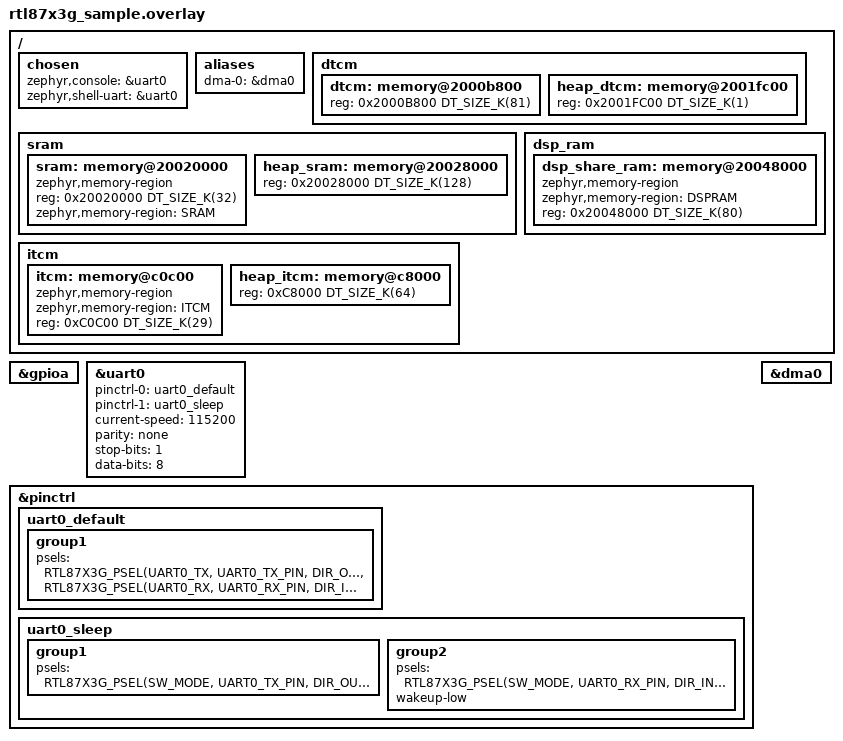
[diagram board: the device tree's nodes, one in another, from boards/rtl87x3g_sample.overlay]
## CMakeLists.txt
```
#
# Copyright (c) 2026, Realtek Semiconductor Corporation
#
# SPDX-License-Identifier: LicenseRef-Realtek-5-Clause
#

message(STATUS "CMAKELIST FOLDER: ${CMAKE_CURRENT_SOURCE_DIR}")

cmake_minimum_required(VERSION 3.20.0)

#===========version generation===========
include(${CMAKE_CURRENT_SOURCE_DIR}/../../cmake/version_generate.cmake)
generate_version()
#===========version generation===========
#===========post build===========
# post build should be called before find_package
include(${CMAKE_CURRENT_SOURCE_DIR}/../../cmake/post_build.cmake)
rtk_post_build()
#===========post build===========

find_package(Zephyr REQUIRED HINTS $ENV{ZEPHYR_BASE})
project(ble_central)

FILE(GLOB app_sources src/*.c)
target_sources(app PRIVATE
  ${app_sources}
  )

set(sources
   ${ZEPHYR_REALTEK_APP_MODULE_DIR}/subsys/bluetooth/gatt_client/bt_ext_ftl.c
   ${ZEPHYR_REALTEK_APP_MODULE_DIR}/subsys/bluetooth/gatt_client/gattc_tbl_storage.c
   )

set(headers
    #header files from app
	src/
    #header files from libs
    ${ZEPHYR_REALTEK_APP_MODULE_DIR}/subsys/bluetooth/gatt_client
    )

foreach(header ${headers})
    if(EXISTS ${header})
        zephyr_include_directories(${header})
    else()
        message(FATAL_ERROR "header file directory does not exist: ${header}. Current cmakelist: ${CMAKE_CURRENT_SOURCE_DIR}")
    endif()
endforeach()

foreach(src ${sources})
    if(EXISTS ${src})
        target_sources(app PRIVATE ${src})
    else()
        message(FATAL_ERROR "source file does not exist: ${src}. Current cmakelist: ${CMAKE_CURRENT_SOURCE_DIR}")
    endif()
endforeach()

target_precompile_headers(app PUBLIC
	          ${CMAKE_CURRENT_SOURCE_DIR}/src/app_lea_cap_ini_flags.h
			  )

target_include_directories(app PRIVATE src)
```

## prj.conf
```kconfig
# nothing here
CONFIG_REALTEK_SUBSYS_BLE_MGR=y
CONFIG_REALTEK_SUBSYS_SYSM=y
CONFIG_REALTEK_SUBSYS_BLE_AUDIO=y

# Network shell
CONFIG_SERIAL=y
CONFIG_UART_CONSOLE=y
CONFIG_UART_INTERRUPT_DRIVEN=y
CONFIG_UART_ASYNC_API=y
CONFIG_SHELL=y
CONFIG_SHELL_BACKEND_SERIAL=y
CONFIG_LOG_RTK=n
CONFIG_PRINTK=y
CONFIG_HEAP_MEM_POOL_SIZE=1024
CONFIG_CONSOLE=y
#CONFIG_STDOUT_CONSOLE=y

#CONFIG_UART_SHELL_ON_DEV_NAME="UART_2"
#CONFIG_SHELL_PROMPT_UART="uart:~$ "
```

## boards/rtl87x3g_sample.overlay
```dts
/*
 * Copyright(c) 2024, Realtek Semiconductor Corporation.
 *
 * SPDX-License-Identifier: Apache-2.0
 */

#include <zephyr/dt-bindings/gpio/realtek-rtl87x3g-gpio.h>
#include <dt-bindings/pinctrl/rtl87x3g-pinctrl.h>
#include <dt-bindings/input/input-event-codes.h>
#include "../board.h"

&gpioa {
	status = "okay";
};

/ {
    chosen {
        zephyr,console = &uart0;
        zephyr,shell-uart = &uart0;
    };
};

/**
#define GDMA_Handshake_UART0_TX                                     (0)
#define GDMA_Handshake_UART0_RX                                     (1)
#define GDMA_Handshake_UART2_TX                                     (2)
#define GDMA_Handshake_UART2_RX                                     (3)
#define GDMA_Handshake_UART3_TX                                     (48)
#define GDMA_Handshake_UART3_RX                                     (49)
#define GDMA_Handshake_UART4_TX                                     (50)
#define GDMA_Handshake_UART4_RX                                     (51)
#define GDMA_Handshake_UART5_TX                                     (52)
#define GDMA_Handshake_UART5_RX                                     (53)
*/

&uart0 {
	pinctrl-0 = <&uart0_default>;
	pinctrl-1 = <&uart0_sleep>;
	pinctrl-names = "default", "sleep";
	status = "okay";
	current-speed = <115200>;
	parity = "none";
	stop-bits = "1";
	data-bits = <8>;
	//dmas = <&dma0 2 3 0xa>, <&dma0 3 2 0x10021>;
	//dma-names = "rx", "tx";
};

&pinctrl
{
	uart0_default:uart0_default {
		group1 {
			psels = <RTL87X3G_PSEL(UART0_TX, UART0_TX_PIN, DIR_OUT, DRV_HIGH, PULL_UP)>,
			<RTL87X3G_PSEL(UART0_RX, UART0_RX_PIN, DIR_IN, DRV_HIGH, PULL_UP)>;
		};
	};

	uart0_sleep:uart0_sleep {
		group1 {
			psels = <RTL87X3G_PSEL(SW_MODE, UART0_TX_PIN, DIR_OUT, DRV_HIGH, PULL_UP)>;
		};
		group2 {
			psels = <RTL87X3G_PSEL(SW_MODE, UART0_RX_PIN, DIR_IN, DRV_HIGH, PULL_UP)>;
			wakeup-low;
		};
	};
};

&dma0 {
	status = "okay";
};

&gpioa {
	status = "okay";
};

/*delete-node only support nodes with lable */
/delete-node/ &dtcm;
/delete-node/ &heap_dtcm;
/delete-node/ &sram;
/delete-node/ &heap_sram;
/delete-node/ &itcm;
/delete-node/ &heap_itcm;
/delete-node/ &dsp_share_ram;

/ {
	aliases {
		dma-0 = &dma0;
    };

	/* DTCM addr: 0x20000000~0x20020000, total size: 128KByte.
	 * The front 46Kbyte was taken by RTK internal.
	 * If users wants to increase global variables and zephyr static heap,
	 * please follow the steps:
	 * 1. increase dtcm size value "reg = <0x2000B800 DT_SIZE_K(NEW_SIZE)>"
	 * 2. modify heap_dtcm addr label "heap_dtcm: memory@NEW_ADDR"
	 * 3. modify heap_dtcm reg addr "reg = <NEW_ADDR DT_SIZE_K(NEW_SIZE)>"
	 * 4. decrease heap_dtcm size value "reg = <NEW_ADDR DT_SIZE_K(NEW_SIZE)>"
	 * Warning:
	 * 1. the dtcm address should NOT modified!
	 * 2. the dtcm plus heap_dtcm size should NOT exceed 82KByte!
	 */
	dtcm {
		dtcm: memory@2000b800 {
			device_type = "dtcm region";
			reg = <0x2000B800 DT_SIZE_K(81)>;
		};
		heap_dtcm: memory@2001fc00 {
			device_type = "heap dtcm region";
			reg = <0x2001FC00 DT_SIZE_K(1)>;
		};
	};
	/* sram addr: 0x20020000~0x20048000, total size: 160KByte.
	 * call zephyr_code_relocate(FILES xxx.x LOCATION SRAM) at cmakelist could relocate variables on sram.
	 * for more information, please refer to https://docs.zephyrproject.org/latest/kernel/code-relocation.html
	 * If users wants to increase sram size, please follow the steps:
	 * 1. increase sram size value "reg = <0x20020000 DT_SIZE_K(NEW_SIZE)>"
	 * 2. modify heap_sram addr label "heap_sram: memory@NEW_ADDR"
	 * 3. modify heap_sram reg addr "reg = <NEW_ADDR DT_SIZE_K(NEW_SIZE)>"
	 * 4. decrease heap_sram size value "reg = <NEW_ADDR DT_SIZE_K(NEW_SIZE)>"
	 * Warning:
	 * 1. the sram address should NOT modified!
	 * 2. the sram plus heap_sram size should NOT exceed 160KByte!
	 */
	sram {
		sram: memory@20020000 {
			device_type = "sram region";
			compatible = "zephyr,memory-region", "mmio-sram";
			reg = <0x20020000 DT_SIZE_K(32)>;
			zephyr,memory-region = "SRAM";
		};
		heap_sram: memory@20028000 {
			device_type = "heap sram region";
			reg = <0x20028000 DT_SIZE_K(128)>;
		};
	};

	itcm {
		itcm: memory@c0c00 {
			device_type = "itcm region";
			compatible = "zephyr,memory-region", "arm,itcm";
			zephyr,memory-region = "ITCM";
			reg = <0xC0C00 DT_SIZE_K(29)>;
		};
		heap_itcm: memory@c8000 {
			device_type = "heap itcm region";
			reg = <0xC8000 DT_SIZE_K(64)>;
		};
	};

	dsp_ram {
		dsp_share_ram: memory@20048000 {
			compatible = "zephyr,memory-region";
			device_type = "dsp_share_ram region";
			zephyr,memory-region = "DSPRAM";
			reg = <0x20048000 DT_SIZE_K(80)>;
		};
	};
};
```

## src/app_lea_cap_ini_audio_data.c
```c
/*
 * Copyright (c) 2026, Realtek Semiconductor Corporation
 *
 * SPDX-License-Identifier: LicenseRef-Realtek-5-Clause
 */

#include "os_queue.h"
#include "stdlib.h"
#include "trace.h"
#include "gap.h"
#include "gap_iso_data.h"
#include "bt_direct_msg.h"
#include "app_lea_cap_ini_main.h"
#include "app_lea_cap_ini_audio_data.h"
#include "ble_audio_def.h"
#include "codec_qos.h"
#if APP_LEA_INPUT_AUDIO_DATA_TEST
#include "app_timer.h"
#endif

#if APP_LEA_INPUT_AUDIO_DATA_TEST
typedef enum
{
    APP_LEA_SEND_ISO_DATA = 0x00,
} T_APP_LEA_TIMER;

static uint8_t app_lea_timer_idx_send_iso_data = 0;
static uint8_t app_lea_timer_id = 0;

const uint8_t lc3_16_2_encoded_data[40] = {0x46, 0xC2, 0x6C, 0x27, 0x41, 0x23, 0x1E, 0x02, 0xE6, 0x7A, 0x04,
                                           0xAB, 0x54, 0x34, 0xFB, 0x6A, 0x0A, 0x24, 0x02, 0x8A, 0xFA, 0x00,
                                           0x00, 0x39, 0x4F, 0x96, 0x0D, 0x38, 0xA7, 0x57, 0xE2, 0x24, 0x56,
                                           0x5F, 0xF1, 0xCB, 0x97, 0x20, 0xF8, 0x9B
                                          };
const uint8_t lc3_16_2_2c_encoded_data[80] = {0x46, 0xC2, 0x6C, 0x27, 0x41, 0x23, 0x1E, 0x02, 0xE6, 0x7A, 0x04,
                                              0xAB, 0x54, 0x34, 0xFB, 0x6A, 0x0A, 0x24, 0x02, 0x8A, 0xFA, 0x00,
                                              0x00, 0x39, 0x4F, 0x96, 0x0D, 0x38, 0xA7, 0x57, 0xE2, 0x24, 0x56,
                                              0x5F, 0xF1, 0xCB, 0x97, 0x20, 0xF8, 0x9B,
                                              0x46, 0xC2, 0x6C, 0x27, 0x41, 0x23, 0x1E, 0x02, 0xE6, 0x7A, 0x04,
                                              0xAB, 0x54, 0x34, 0xFB, 0x6A, 0x0A, 0x24, 0x02, 0x8A, 0xFA, 0x00,
                                              0x00, 0x39, 0x4F, 0x96, 0x0D, 0x38, 0xA7, 0x57, 0xE2, 0x24, 0x56,
                                              0x5F, 0xF1, 0xCB, 0x97, 0x20, 0xF8, 0x9B
                                             };
const uint8_t lc3_16_1_encoded_data[30] = {0x1D,  0x92,  0xB3,  0x67,  0xDE,  0xF5,  0xD0,  0x46,  0xEB,  0xC7,  0xDD,  0x69,  0x89,  0xD8,
                                           0xEA,  0xD5,  0x42,  0x22,  0x4C,  0xBB,  0x53,  0xF9,  0x0D,  0xED,  0xD8,  0xE5,  0x3C,  0xA0,
                                           0xCA,  0x57
                                          };
void app_lea_test_iso_data_send(void)
{
    T_GAP_CAUSE cause = GAP_CAUSE_SUCCESS;
    T_APP_LEA_ISO_CHANN *p_iso_chann = NULL;

    for (uint8_t i = 0; i < app_db.iso_input_queue.count; i++)
    {
        p_iso_chann = (T_APP_LEA_ISO_CHANN *)os_queue_peek(&app_db.iso_input_queue, i);
        if (p_iso_chann->iso_sdu_len != 0)
        {
            cause = gap_iso_send_data((uint8_t *)p_iso_chann->p_encoded_data,
                                      p_iso_chann->iso_conn_handle,
                                      p_iso_chann->iso_sdu_len,
                                      false,
                                      (p_iso_chann->pkt_seq_num * p_iso_chann->sdu_interval),
                                      p_iso_chann->pkt_seq_num);
            if (cause != GAP_CAUSE_SUCCESS)
            {
                goto error;
            }
        }
        p_iso_chann->pkt_seq_num++;
    }
    return;
error:
    APP_PRINT_ERROR1("app_lea_test_iso_data_send: failed, cause 0x%x", cause);
    return;
}

static void app_lea_timer_timeout_cb(uint8_t timer_evt, uint16_t param)
{
    switch (timer_evt)
    {
    case APP_LEA_SEND_ISO_DATA:
        {
            app_lea_test_iso_data_send();
        }
        break;

    default:
        break;
    }
}

static void app_lea_test_start_iso_data_timer(uint32_t timeout_ms)
{
    if (app_lea_timer_id == 0)
    {
        app_timer_reg_cb(app_lea_timer_timeout_cb, &app_lea_timer_id);
    }
    app_start_timer(&app_lea_timer_idx_send_iso_data, "iso_data",
                    app_lea_timer_id, APP_LEA_SEND_ISO_DATA, 0, true,
                    timeout_ms);
}


void app_lea_test_iso_chann_remove(void)
{
    APP_PRINT_INFO1("app_lea_test_iso_chann_remove: iso_input_queue %d",
                    app_db.iso_input_queue.count);
    if (app_db.iso_input_queue.count == 0)
    {
        app_stop_timer(&app_lea_timer_idx_send_iso_data);
    }
}

void app_lea_test_iso_chann_add(T_APP_LEA_ISO_CHANN *p_iso_chann)
{
    uint8_t err_idx = 0;

    codec_max_sdu_len_get(&p_iso_chann->codec_data, &p_iso_chann->iso_sdu_len);
    codec_sdu_interval_get(&p_iso_chann->codec_data, &p_iso_chann->sdu_interval);
    p_iso_chann->pkt_seq_num = 1;

    if (p_iso_chann->codec_data.sample_frequency == SAMPLING_FREQUENCY_CFG_16K)
    {
        if (p_iso_chann->codec_data.frame_duration == FRAME_DURATION_CFG_10_MS)
        {
            if (p_iso_chann->iso_sdu_len == sizeof(lc3_16_2_encoded_data))
            {
                p_iso_chann->p_encoded_data = lc3_16_2_encoded_data;
            }
            else if (p_iso_chann->iso_sdu_len == sizeof(lc3_16_2_2c_encoded_data))
            {
                p_iso_chann->p_encoded_data = lc3_16_2_2c_encoded_data;
            }
            else
            {
                err_idx = 3;
                goto failed;
            }
        }
        else if (p_iso_chann->codec_data.frame_duration == FRAME_DURATION_CFG_7_5_MS)
        {
            if (p_iso_chann->iso_sdu_len == sizeof(lc3_16_1_encoded_data))
            {
                p_iso_chann->p_encoded_data = lc3_16_1_encoded_data;
            }
            else
            {
                err_idx = 4;
                goto failed;
            }
        }
    }
    else
    {
        err_idx = 10;
        goto failed;
    }
    APP_PRINT_INFO2("app_lea_test_iso_chann_add: sdu %d, interval %d", p_iso_chann->iso_sdu_len,
                    p_iso_chann->sdu_interval / 1000);

    app_lea_test_start_iso_data_timer(p_iso_chann->sdu_interval / 1000);

    return;
failed:
    APP_PRINT_ERROR1("app_lea_test_iso_chann_add: failed err_idx %d", err_idx);
    return;
}
#endif

static T_APP_LEA_ISO_CHANN *app_lea_find_iso_chann(uint16_t iso_conn_handle, uint8_t direction)
{
    int i;
    T_APP_LEA_ISO_CHANN *p_iso_chann = NULL;
    if (direction == DATA_PATH_INPUT_FLAG)
    {
        for (i = 0; i < app_db.iso_input_queue.count; i++)
        {
            p_iso_chann = (T_APP_LEA_ISO_CHANN *)os_queue_peek(&app_db.iso_input_queue, i);
            if (p_iso_chann->iso_conn_handle == iso_conn_handle)
            {
                return p_iso_chann;
            }
        }
    }
    else
    {
        for (i = 0; i < app_db.iso_output_queue.count; i++)
        {
            p_iso_chann = (T_APP_LEA_ISO_CHANN *)os_queue_peek(&app_db.iso_output_queue, i);
            if (p_iso_chann->iso_conn_handle == iso_conn_handle)
            {
                return p_iso_chann;
            }
        }
    }
    return NULL;
}

T_APP_LEA_ISO_CHANN *app_lea_add_iso_chann(uint16_t iso_conn_handle, uint8_t direction)
{
    T_APP_LEA_ISO_CHANN *p_iso_chann;

    p_iso_chann = app_lea_find_iso_chann(iso_conn_handle, direction);
    if (p_iso_chann)
    {
        return p_iso_chann;
    }
    p_iso_chann = calloc(1, sizeof(T_APP_LEA_ISO_CHANN));
    if (p_iso_chann)
    {
        p_iso_chann->iso_conn_handle = iso_conn_handle;
        p_iso_chann->path_direction = direction;
        if (direction == DATA_PATH_INPUT_FLAG)
        {
            os_queue_in(&app_db.iso_input_queue, p_iso_chann);
        }
        else
        {
            os_queue_in(&app_db.iso_output_queue, p_iso_chann);
        }
        APP_PRINT_INFO2("app_lea_add_iso_chann: iso_conn_handle 0x%x, direction %d",
                        iso_conn_handle, direction);
    }
    return p_iso_chann;
}

static void app_lea_remove_iso_chann(uint16_t iso_conn_handle, uint8_t direction)
{
    int i;
    T_APP_LEA_ISO_CHANN *p_iso_chann = NULL;
    APP_PRINT_INFO2("app_lea_remove_iso_chann: iso_conn_handle 0x%x, direction %d",
                    iso_conn_handle, direction);
    if (direction == DATA_PATH_INPUT_FLAG)
    {
        for (i = 0; i < app_db.iso_input_queue.count; i++)
        {
            p_iso_chann = (T_APP_LEA_ISO_CHANN *)os_queue_peek(&app_db.iso_input_queue, i);
            if (p_iso_chann->iso_conn_handle == iso_conn_handle)
            {
                os_queue_delete(&app_db.iso_input_queue, p_iso_chann);
                free(p_iso_chann);
#if APP_LEA_INPUT_AUDIO_DATA_TEST
                app_lea_test_iso_chann_remove();
#endif
                return;
            }
        }
    }
    else
    {
        for (i = 0; i < app_db.iso_output_queue.count; i++)
        {
            p_iso_chann = (T_APP_LEA_ISO_CHANN *)os_queue_peek(&app_db.iso_output_queue, i);
            if (p_iso_chann->iso_conn_handle == iso_conn_handle)
            {
                os_queue_delete(&app_db.iso_output_queue, p_iso_chann);
                free(p_iso_chann);
                return;
            }
        }
    }
}


void app_lea_handle_data_path_setup(T_LEA_SETUP_DATA_PATH *p_data)
{
    T_APP_LEA_ISO_CHANN *p_iso_chann = app_lea_find_iso_chann(p_data->iso_conn_handle,
                                                              p_data->path_direction);
    uint8_t chnl_cnt;
    uint8_t blocks_num = 1;

    if (p_iso_chann != NULL)
    {
        APP_PRINT_WARN0("app_lea_handle_data_path_setup: iso channel already exist");
        return;
    }
    else
    {
        p_iso_chann = app_lea_add_iso_chann(p_data->iso_conn_handle,
                                            p_data->path_direction);
        if (p_iso_chann == NULL)
        {
            return;
        }
        p_iso_chann->iso_mode = p_data->iso_mode;
    }
    p_iso_chann->codec_data = p_data->codec_parsed_data;
    p_iso_chann->presentation_delay = p_data->presentation_delay;
    p_iso_chann->pkt_seq_num = 0;
    if (p_iso_chann->codec_data.audio_channel_allocation == AUDIO_LOCATION_MONO)
    {
        chnl_cnt = 1;
    }
    else
    {
        chnl_cnt = __builtin_popcount(p_iso_chann->codec_data.audio_channel_allocation);
    }
    if (p_iso_chann->codec_data.type_exist & CODEC_CFG_TYPE_BLOCKS_PER_SDU_EXIST)
    {
        blocks_num = p_iso_chann->codec_data.codec_frame_blocks_per_sdu;
    }
    p_iso_chann->frame_num = blocks_num * chnl_cnt;

    APP_PRINT_INFO6("app_lea_handle_data_path_setup: cis handle 0x%04x, frame_num %d, "
                    "dir %u, sample_frequency 0x%x, audio_channel_allocation 0x%08x, presentation_delay 0x%x",
                    p_iso_chann->iso_conn_handle, p_iso_chann->frame_num,
                    p_iso_chann->path_direction,
                    p_iso_chann->codec_data.sample_frequency,
                    p_iso_chann->codec_data.audio_channel_allocation,
                    p_iso_chann->presentation_delay);
#if APP_LEA_INPUT_AUDIO_DATA_TEST
    if (p_data->path_direction == DATA_PATH_INPUT_FLAG)
    {
        app_lea_test_iso_chann_add(p_iso_chann);
    }
#endif
}

void app_lea_handle_data_path_remove(T_LEA_REMOVE_DATA_PATH *p_data)
{
    T_APP_LEA_ISO_CHANN *p_iso_chann = app_lea_find_iso_chann(p_data->iso_conn_handle,
                                                              p_data->path_direction);
    if (p_iso_chann != NULL)
    {
        app_lea_remove_iso_chann(p_data->iso_conn_handle, p_data->path_direction);
    }
}

void app_lea_data_direct_cb(uint8_t cb_type, void *p_cb_data)
{
    T_BT_DIRECT_CB_DATA *p_data = (T_BT_DIRECT_CB_DATA *)p_cb_data;

    switch (cb_type)
    {
    case BT_DIRECT_MSG_ISO_DATA_IND:
        {
#if 0
            APP_PRINT_TRACE5("app_lea_data_direct_cb: conn_handle 0x%x, iso_sdu_len %d, pkt_seq_num 0x%x, time_stamp 0x%x, pkt_status_flag 0x%x",
                             p_data->p_bt_direct_iso->conn_handle, p_data->p_bt_direct_iso->iso_sdu_len,
                             p_data->p_bt_direct_iso->pkt_seq_num, p_data->p_bt_direct_iso->time_stamp,
                             p_data->p_bt_direct_iso->pkt_status_flag);
#endif
#if 0
            uint8_t *p_iso_data = p_data->p_bt_direct_iso->p_buf + p_data->p_bt_direct_iso->offset;
            APP_PRINT_INFO5("app_lea_data_direct_cb: BT_DIRECT_MSG_ISO_DATA_IND, iso_sdu_len 0x%x, p_buf %p, offset %d, p_data %p, data %b",
                            p_data->p_bt_direct_iso->iso_sdu_len, p_data->p_bt_direct_iso->p_buf,
                            p_data->p_bt_direct_iso->offset, p_iso_data, TRACE_BINARY(p_data->p_bt_direct_iso->iso_sdu_len,
                                                                                      p_iso_data));
#endif
            APP_PRINT_TRACE5("app_lea_data_direct_cb: conn_handle 0x%x, iso_sdu_len %d, pkt_seq_num 0x%x, time_stamp 0x%x, pkt_status_flag 0x%x",
                             p_data->p_bt_direct_iso->conn_handle, p_data->p_bt_direct_iso->iso_sdu_len,
                             p_data->p_bt_direct_iso->pkt_seq_num, p_data->p_bt_direct_iso->time_stamp,
                             p_data->p_bt_direct_iso->pkt_status_flag);

            if (p_data->p_bt_direct_iso->pkt_status_flag != ISOCH_DATA_PKT_STATUS_VALID_DATA)
            {
                gap_iso_data_cfm(p_data->p_bt_direct_iso->p_buf);
                break;
            }

            T_APP_LEA_ISO_CHANN *p_iso_chann = app_lea_find_iso_chann(p_data->p_bt_direct_iso->conn_handle,
                                                                      DATA_PATH_OUTPUT_FLAG);
            if (p_iso_chann != NULL)
            {
#if 0
                //Just for sample. Application can send the data to DSP.
                uint16_t written_len;
                T_AUDIO_STREAM_STATUS status;

                if (p_data->p_bt_direct_iso->iso_sdu_len != 0)
                {
                    status = AUDIO_STREAM_STATUS_CORRECT;
                }
                else
                {
                    status = AUDIO_STREAM_STATUS_LOST;
                }
                audio_track_write(handle, p_data->p_bt_direct_iso->time_stamp,
                                  p_data->p_bt_direct_iso->pkt_seq_num,
                                  status,
                                  p_iso_chann->frame_num,
                                  p_data->p_bt_direct_iso->p_buf + p_data->p_bt_direct_iso->offset,
                                  p_data->p_bt_direct_iso->iso_sdu_len,
                                  &written_len);
#endif
            }

            gap_iso_data_cfm(p_data->p_bt_direct_iso->p_buf);
        }
        break;

    default:
        APP_PRINT_ERROR1("app_lea_data_direct_cb: unhandled cb_type 0x%x", cb_type);
        break;
    }
}

void app_lea_audio_data_init(void)
{
    os_queue_init(&app_db.iso_input_queue);
    os_queue_init(&app_db.iso_output_queue);
    gap_register_direct_cb(app_lea_data_direct_cb);
}
```

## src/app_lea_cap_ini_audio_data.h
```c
/*
 * Copyright (c) 2026, Realtek Semiconductor Corporation
 *
 * SPDX-License-Identifier: LicenseRef-Realtek-5-Clause
 */

#ifndef _APP_LEA_CAP_INI_AUDIO_DATA_H_
#define _APP_LEA_CAP_INI_AUDIO_DATA_H_

#ifdef  __cplusplus
extern "C" {
#endif      /* __cplusplus */

#include "codec_def.h"
#include "ble_isoch_def.h"

#define CIG_ISO_MODE        0x01
#define BIG_ISO_MODE        0x02

typedef struct t_lea_iso_chann
{
    struct t_lea_iso_chann     *p_next;
    uint8_t                     iso_mode;
    uint8_t                     frame_num;
    uint8_t                     path_direction;   //DATA_PATH_INPUT_FLAG or DATA_PATH_OUTPUT_FLAG
    uint16_t                    iso_conn_handle;
    uint16_t                    pkt_seq_num;
    uint32_t                    presentation_delay;
    T_CODEC_CFG                 codec_data;
#if APP_LEA_INPUT_AUDIO_DATA_TEST
    uint16_t                    iso_sdu_len;
    uint32_t                    sdu_interval;
    const uint8_t              *p_encoded_data;
#endif
} T_APP_LEA_ISO_CHANN;

typedef struct
{
    uint8_t iso_mode;
    uint8_t path_direction;//DATA_PATH_INPUT_FLAG or DATA_PATH_OUTPUT_FLAG
    uint16_t iso_conn_handle;
    uint32_t presentation_delay;
    T_CODEC_CFG codec_parsed_data;
} T_LEA_SETUP_DATA_PATH;

typedef struct
{
    uint8_t iso_mode;
    uint8_t path_direction;//DATA_PATH_INPUT_FLAG or DATA_PATH_OUTPUT_FLAG
    uint16_t iso_conn_handle;
} T_LEA_REMOVE_DATA_PATH;

void app_lea_handle_data_path_setup(T_LEA_SETUP_DATA_PATH *p_data);
void app_lea_handle_data_path_remove(T_LEA_REMOVE_DATA_PATH *p_data);
void app_lea_audio_data_init(void);

#ifdef  __cplusplus
}
#endif      /*  __cplusplus */

#endif
```

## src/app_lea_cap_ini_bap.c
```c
/*
 * Copyright (c) 2026, Realtek Semiconductor Corporation
 *
 * SPDX-License-Identifier: LicenseRef-Realtek-5-Clause
 */

#include "stdlib.h"
#include "ble_audio.h"
#include "bap.h"
#include "trace.h"
#include "app_lea_cap_ini_main.h"
#include "app_lea_cap_ini_bap.h"
#include "ble_audio.h"
#include "ble_audio_def.h"
#include "bass_client.h"
#include "metadata_def.h"
#include "base_data_parse.h"
#include "base_data_generate.h"

#if (BAP_BROADCAST_ASSISTANT && BAP_BROADCAST_SOURCE)
void app_lea_link_init_brs_char(T_APP_LE_LINK *p_link, uint8_t brs_char_num)
{
    if (p_link->brs_char_tbl)
    {
        free(p_link->brs_char_tbl);
        p_link->brs_char_num = 0;
        p_link->brs_char_tbl = NULL;
    }
    if (brs_char_num)
    {
        p_link->brs_char_tbl = calloc(1, brs_char_num * sizeof(T_BASS_BRS_CHAR_DB));
        if (p_link->brs_char_tbl)
        {
            T_BASS_BRS_DATA *p_brs_data;

            p_link->brs_char_num = brs_char_num;
            for (uint8_t i = 0; i < brs_char_num; i++)
            {
                p_link->brs_char_tbl[i].instance_id = i;
                p_brs_data = bass_get_brs_data(p_link->conn_handle, i);
                if (p_brs_data)
                {
                    if (p_brs_data->brs_is_used)
                    {
                        p_link->brs_char_tbl[i].brs_is_used = true;
                        p_link->brs_char_tbl[i].source_id = p_brs_data->source_id;
                        p_link->brs_char_tbl[i].handle = app_lea_bsrc_get_handle(p_brs_data->source_address,
                                                                                 p_brs_data->source_address_type,
                                                                                 p_brs_data->source_adv_sid, p_brs_data->broadcast_id);
                    }
                }
            }
        }
    }
}

T_BASS_BRS_CHAR_DB *app_lea_link_find_brs_char(T_APP_LE_LINK *p_link, uint8_t instance_id)
{
    if (instance_id < p_link->brs_char_num)
    {
        return &p_link->brs_char_tbl[instance_id];
    }
    return NULL;
}

T_BASS_BRS_CHAR_DB *app_lea_link_find_brs_char_by_source_handle(T_APP_LE_LINK *p_link,
                                                                T_BROADCAST_SOURCE_HANDLE source_handle)
{
    for (uint8_t i = 0; i < p_link->brs_char_num; i++)
    {
        if (p_link->brs_char_tbl[i].brs_is_used &&
            p_link->brs_char_tbl[i].handle == source_handle)
        {
            return &p_link->brs_char_tbl[i];
        }
    }
    APP_PRINT_TRACE1("app_lea_link_find_brs_char_by_source_handle: not find source_handle %p",
                     source_handle);
    return NULL;
}

void app_lea_link_update_brs_char(T_APP_LE_LINK *p_link, T_BASS_CLIENT_BRS_DATA *p_data)
{
    T_BASS_BRS_CHAR_DB *p_brs_char = app_lea_link_find_brs_char(p_link, p_data->char_instance_id);

    if (p_brs_char)
    {
        if (p_brs_char->brs_is_used != p_data->p_brs_data->brs_is_used)
        {
            if (p_data->p_brs_data->brs_is_used)
            {
                p_brs_char->brs_is_used = true;
                p_brs_char->source_id = p_data->p_brs_data->source_id;
                p_brs_char->handle = app_lea_bsrc_get_handle(p_data->p_brs_data->source_address,
                                                             p_data->p_brs_data->source_address_type,
                                                             p_data->p_brs_data->source_adv_sid, p_data->p_brs_data->broadcast_id);
            }
            else
            {
                p_brs_char->brs_is_used = false;
                p_brs_char->source_id = 0;
                p_brs_char->handle = NULL;
            }
        }
    }
}

void app_lea_link_brs_char_add_source_handle(void)
{
    T_APP_LE_LINK *p_link = NULL;
    uint8_t i;

    for (i = 0; i < APP_MAX_BLE_LINK_NUM; i++)
    {
        if (app_db.le_link[i].used == true &&
            app_db.le_link[i].brs_char_tbl != NULL)
        {
            p_link = &app_db.le_link[i];
            for (uint8_t j = 0; j < p_link->brs_char_num; j++)
            {
                if (p_link->brs_char_tbl[j].brs_is_used &&
                    p_link->brs_char_tbl[j].handle == NULL)
                {
                    T_BASS_BRS_DATA *p_brs_data = bass_get_brs_data(p_link->conn_handle, j);

                    if (p_brs_data)
                    {
                        p_link->brs_char_tbl[j].handle = app_lea_bsrc_get_handle(p_brs_data->source_address,
                                                                                 p_brs_data->source_address_type,
                                                                                 p_brs_data->source_adv_sid, p_brs_data->broadcast_id);
                    }
                }
            }
        }
    }
}

void app_lea_ini_bst_reception_stop(T_BLE_AUDIO_GROUP_HANDLE group_handle,
                                    T_BROADCAST_SOURCE_HANDLE source_handle)
{
    uint8_t dev_num;
    T_AUDIO_DEV_INFO *p_dev_tbl;

    dev_num = ble_audio_group_get_dev_num(group_handle);
    if (dev_num)
    {
        p_dev_tbl = calloc(1, dev_num * sizeof(T_AUDIO_DEV_INFO));
        if (p_dev_tbl)
        {
            if (ble_audio_group_get_info(group_handle, &dev_num, p_dev_tbl))
            {
                for (uint8_t j = 0; j < dev_num; j++)
                {
                    if (p_dev_tbl[j].is_used && p_dev_tbl[j].conn_state == GAP_CONN_STATE_CONNECTED)
                    {
                        T_APP_LE_LINK *p_link = app_link_find_le_link_by_conn_handle(p_dev_tbl[j].conn_handle);
                        if (p_link)
                        {
                            if (p_link->lea_disc_flags & LEA_LINK_DISC_BASS_DONE)
                            {
                                T_BASS_BRS_CHAR_DB *p_brs_char = app_lea_link_find_brs_char_by_source_handle(p_link, source_handle);
                                if (p_brs_char)
                                {
                                    T_BASS_CP_MODIFY_SOURCE modify_src = {0};
                                    T_BASS_CP_BIS_INFO bis_info = {0};

                                    modify_src.source_id = p_brs_char->source_id;
                                    modify_src.pa_sync = BASS_PA_NOT_SYNC;
                                    modify_src.pa_interval = BASS_PA_INTERVAL_UNKNOWN;
                                    modify_src.num_subgroups = 1;
                                    bis_info.bis_sync = 0;
                                    bis_info.metadata_len = 0;
                                    bis_info.p_metadata = NULL;
                                    modify_src.bis_info_size = modify_src.num_subgroups * sizeof(bis_info) + bis_info.metadata_len;
                                    modify_src.p_cp_bis_info = &bis_info;
                                    bass_cp_modify_source(p_link->conn_handle, &modify_src, false);
                                }
                            }
                        }
                    }
                }
            }
            free(p_dev_tbl);
        }
    }
}

void app_lea_ini_bst_reception_remove(T_BLE_AUDIO_GROUP_HANDLE group_handle,
                                      T_BROADCAST_SOURCE_HANDLE source_handle)
{
    uint8_t dev_num;
    T_AUDIO_DEV_INFO *p_dev_tbl;

    dev_num = ble_audio_group_get_dev_num(group_handle);
    if (dev_num)
    {
        p_dev_tbl = calloc(1, dev_num * sizeof(T_AUDIO_DEV_INFO));
        if (p_dev_tbl)
        {
            if (ble_audio_group_get_info(group_handle, &dev_num, p_dev_tbl))
            {
                for (uint8_t j = 0; j < dev_num; j++)
                {
                    if (p_dev_tbl[j].is_used && p_dev_tbl[j].conn_state == GAP_CONN_STATE_CONNECTED)
                    {
                        T_APP_LE_LINK *p_link = app_link_find_le_link_by_conn_handle(p_dev_tbl[j].conn_handle);
                        if (p_link)
                        {
                            APP_PRINT_TRACE2("app_lea_ini_bst_reception_remove: conn_handle 0x%x, lea_disc_flags 0x%x",
                                             p_dev_tbl[j].conn_handle, p_link->lea_disc_flags);
                            if (p_link->lea_disc_flags & LEA_LINK_DISC_BASS_DONE)
                            {
                                T_BASS_BRS_CHAR_DB *p_brs_char = app_lea_link_find_brs_char_by_source_handle(p_link, source_handle);
                                if (p_brs_char)
                                {
                                    T_BASS_CP_REMOVE_SOURCE remove_source;
                                    remove_source.source_id = p_brs_char->source_id;
                                    bass_cp_remove_source(p_link->conn_handle, &remove_source, false);
                                }
                            }
                        }
                    }
                }
            }
            free(p_dev_tbl);
        }
    }
}

void app_lea_ini_bst_start(T_BASS_BRS_CHAR_DB *p_brs_char, uint16_t conn_handle)
{
    uint8_t err_idx = 0;
    uint16_t pa_data_len;
    uint8_t *pa_data = NULL;
    T_BASE_DATA_MAPPING *p_base_mapping = NULL;
    uint32_t bis_array;
    T_BASS_CP_BIS_INFO *p_cp_bis_info = NULL;
    uint16_t meta_data_len = 0;
    uint32_t bis_array_temp = 0;
    uint16_t bis_info_size = 0;
    uint8_t *p_meta_data;

    if (base_data_gen_pa_data(app_db.bsrc_db.group1_idx, &pa_data_len, &pa_data) == false)
    {
        err_idx = 1;
        goto ret;
    }
    p_base_mapping = base_data_parse_data(pa_data_len, pa_data);


    bis_array = bap_pacs_check_cfg_by_base_data(p_base_mapping, conn_handle,
                                                (BA_PACS_CHECK_FILTER_CODEC));
    if (bis_array == 0)
    {
        err_idx = 2;
        goto ret;
    }

    if (p_brs_char)
    {
        T_BASS_BRS_DATA *p_brs_data = bass_get_brs_data(conn_handle, p_brs_char->instance_id);
        if (p_brs_data && p_brs_data->p_cp_bis_info != NULL)
        {
            if (p_brs_data->p_cp_bis_info->bis_sync == bis_array)
            {
                err_idx = 0;
                goto ret;
            }
        }
    }
    for (uint8_t i = 0; i < p_base_mapping->num_subgroups; i++)
    {
        if (p_base_mapping->p_subgroup[i].bis_array & bis_array)
        {
            bis_array_temp |= (p_base_mapping->p_subgroup[i].bis_array & bis_array);
        }
        meta_data_len += p_base_mapping->p_subgroup[i].metadata_len;
    }
    if (bis_array != BASS_CP_BIS_SYNC_NO_PREFER && bis_array != bis_array_temp)
    {
        err_idx = 3;
        goto ret;
    }
    bis_info_size = p_base_mapping->num_subgroups * sizeof(
                        T_BASS_CP_BIS_INFO) + meta_data_len;
    p_cp_bis_info = calloc(1, bis_info_size);
    if (p_cp_bis_info == NULL)
    {
        err_idx = 4;
        goto ret;
    }

    p_meta_data = (uint8_t *)(p_cp_bis_info + p_base_mapping->num_subgroups);
    for (uint8_t i = 0; i < p_base_mapping->num_subgroups; i++)
    {
        if (bis_array == BASS_CP_BIS_SYNC_NO_PREFER)
        {
            p_cp_bis_info[i].bis_sync = BASS_CP_BIS_SYNC_NO_PREFER;
        }
        else
        {
            p_cp_bis_info[i].bis_sync = (p_base_mapping->p_subgroup[i].bis_array & bis_array);
        }
        p_cp_bis_info[i].metadata_len = p_base_mapping->p_subgroup[i].metadata_len;
        if (p_cp_bis_info[i].metadata_len > 0)
        {
            memcpy(p_meta_data, p_base_mapping->p_subgroup[i].p_metadata,
                   p_cp_bis_info[i].metadata_len);
            p_cp_bis_info[i].p_metadata = p_meta_data;
            p_meta_data += p_cp_bis_info->metadata_len;
        }
    }

    if (p_brs_char)
    {
        T_BASS_CP_MODIFY_SOURCE modify_src = {0};

        modify_src.bis_info_size = bis_info_size;
        modify_src.p_cp_bis_info = p_cp_bis_info;
        modify_src.num_subgroups = p_base_mapping->num_subgroups;

        modify_src.source_id = p_brs_char->source_id;
        modify_src.pa_sync = BASS_PA_SYNC_PAST;
        modify_src.pa_interval = BASS_PA_INTERVAL_UNKNOWN;

        if (bass_cp_modify_source(conn_handle, &modify_src, false) == false)
        {
            err_idx = 5;
            goto ret;
        }
    }
    else
    {
        T_BASS_CP_ADD_SOURCE add_src = {0};

        add_src.bis_info_size = bis_info_size;
        add_src.p_cp_bis_info = p_cp_bis_info;
        add_src.num_subgroups = p_base_mapping->num_subgroups;

        add_src.advertiser_address_type = app_db.bsrc_db.cfg_local_addr_type;
        memcpy(add_src.advertiser_address, app_db.bsrc_db.source_address, GAP_BD_ADDR_LEN);
        add_src.advertiser_sid = app_db.bsrc_db.source_adv_sid;
        memcpy(add_src.broadcast_id, app_db.bsrc_db.broadcast_id, BROADCAST_ID_LEN);
        add_src.pa_sync = BASS_PA_SYNC_PAST;
        add_src.pa_interval = BASS_PA_INTERVAL_UNKNOWN;

        if (bass_cp_add_source(conn_handle, &add_src, false) == false)
        {
            err_idx = 6;
            goto ret;
        }
    }

    err_idx = 0;
ret:
    if (pa_data)
    {
        free(pa_data);
    }
    if (p_base_mapping)
    {
        base_data_free(p_base_mapping);
    }
    if (p_cp_bis_info)
    {
        free(p_cp_bis_info);
    }
    if (err_idx != 0)
    {
        APP_PRINT_INFO2("app_lea_ini_bst_start: failed, conn_handle 0x%x, err_idx %d", conn_handle,
                        err_idx);
    }
    return;
}

void app_lea_ini_bst_reception_start(T_BLE_AUDIO_GROUP_HANDLE group_handle,
                                     T_BROADCAST_SOURCE_HANDLE source_handle)
{
    uint8_t dev_num;
    T_AUDIO_DEV_INFO *p_dev_tbl;

    if (app_db.bsrc_db.source_handle == NULL ||
        app_db.bsrc_db.state != BROADCAST_SOURCE_STATE_STREAMING)
    {
        return;
    }

    dev_num = ble_audio_group_get_dev_num(group_handle);
    if (dev_num)
    {
        p_dev_tbl = calloc(1, dev_num * sizeof(T_AUDIO_DEV_INFO));
        if (p_dev_tbl)
        {
            if (ble_audio_group_get_info(group_handle, &dev_num, p_dev_tbl))
            {
                for (uint8_t j = 0; j < dev_num; j++)
                {
                    if (p_dev_tbl[j].is_used && p_dev_tbl[j].conn_state == GAP_CONN_STATE_CONNECTED)
                    {
                        T_APP_LE_LINK *p_link = app_link_find_le_link_by_conn_handle(p_dev_tbl[j].conn_handle);
                        if (p_link)
                        {
                            APP_PRINT_TRACE2("app_lea_ini_bst_reception_start: conn_handle 0x%x, lea_disc_flags 0x%x",
                                             p_dev_tbl[j].conn_handle, p_link->lea_disc_flags);
                            if (p_link->lea_disc_flags & LEA_LINK_DISC_BASS_DONE)
                            {
                                T_BASS_BRS_CHAR_DB *p_brs_char;
                                p_brs_char = app_lea_link_find_brs_char_by_source_handle(p_link, source_handle);
                                app_lea_ini_bst_start(p_brs_char, p_link->conn_handle);
                            }
                        }
                    }
                }
            }
            free(p_dev_tbl);
        }
    }
}
#endif

uint16_t app_lea_ini_bap_handle_msg(T_LE_AUDIO_MSG msg, void *buf)
{
    uint16_t cb_result = BLE_AUDIO_CB_RESULT_SUCCESS;
    T_APP_LE_LINK *p_link = NULL;

    switch (msg)
    {
    case LE_AUDIO_MSG_BAP_DIS_ALL_DONE:
        {
            T_BAP_DIS_ALL_DONE *p_data = (T_BAP_DIS_ALL_DONE *)buf;
            APP_PRINT_INFO5("LE_AUDIO_MSG_BAP_DIS_ALL_DONE: conn_handle 0x%x, cause 0x%x, pacs_is_found %d, sink_pac_num %d, source_pac_num %d",
                            p_data->conn_handle,
                            p_data->cause,
                            p_data->pacs_is_found,
                            p_data->sink_pac_num,
                            p_data->source_pac_num);
            APP_PRINT_INFO5("LE_AUDIO_MSG_BAP_DIS_ALL_DONE: ascs_is_found %d, sink_ase_num %d, source_ase_num %d, bass_is_found %d, brs_char_num %d",
                            p_data->ascs_is_found,
                            p_data->sink_ase_num,
                            p_data->source_ase_num,
                            p_data->bass_is_found,
                            p_data->brs_char_num);
            p_link = app_link_find_le_link_by_conn_handle(p_data->conn_handle);
            if (p_link)
            {
                if (p_data->ascs_is_found)
                {
                    p_link->lea_disc_flags |= LEA_LINK_DISC_ASCS_DONE;
                    p_link->lea_srv_found_flags |= LEA_LINK_DISC_ASCS_DONE;
                }
                if (p_data->pacs_is_found)
                {
                    p_link->lea_disc_flags |= LEA_LINK_DISC_PACS_DONE;
                    p_link->lea_srv_found_flags |= LEA_LINK_DISC_PACS_DONE;
                }
#if (BAP_BROADCAST_ASSISTANT && BAP_BROADCAST_SOURCE)
                if (p_data->bass_is_found)
                {
                    p_link->lea_disc_flags |= LEA_LINK_DISC_BASS_DONE;
                    p_link->lea_srv_found_flags |= LEA_LINK_DISC_BASS_DONE;
                    app_lea_link_init_brs_char(p_link, p_data->brs_char_num);
                }
#endif
            }

        }
        break;

#if (BAP_BROADCAST_ASSISTANT && BAP_BROADCAST_SOURCE)
    case LE_AUDIO_MSG_BASS_CLIENT_CP_RESULT:
        {
            T_BASS_CLIENT_CP_RESULT *p_data = (T_BASS_CLIENT_CP_RESULT *)buf;
            APP_PRINT_INFO2("LE_AUDIO_MSG_BASS_CLIENT_CP_RESULT: conn_handle 0x%x, cause 0x%x",
                            p_data->conn_handle,
                            p_data->cause);
        }
        break;

    case LE_AUDIO_MSG_BASS_CLIENT_SYNC_INFO_REQ:
        {
            T_BASS_CLIENT_SYNC_INFO_REQ *p_data = (T_BASS_CLIENT_SYNC_INFO_REQ *)buf;

            APP_PRINT_INFO2("LE_AUDIO_MSG_BASS_CLIENT_SYNC_INFO_REQ: conn_handle 0x%x, char_instance_id %d",
                            p_data->conn_handle,
                            p_data->char_instance_id);
            p_link = app_link_find_le_link_by_conn_handle(p_data->conn_handle);
            if (p_link)
            {
                T_BASS_BRS_CHAR_DB *p_brs_char = app_lea_link_find_brs_char(p_link, p_data->char_instance_id);
                if (p_brs_char != NULL && p_brs_char->handle != NULL)
                {
                    if (ble_audio_check_remote_features(p_data->conn_handle, LE_SUPPORT_FEATURES_MASK_ARRAY_INDEX3,
                                                        LE_SUPPORT_FEATURES_PAST_RECIPIENT_MASK_BIT))
                    {
                        if (le_check_supported_features(LE_SUPPORT_FEATURES_MASK_ARRAY_INDEX3,
                                                        LE_SUPPORT_FEATURES_PAST_SENDER_MASK_BIT))
                        {
                            T_BASS_PAST_SRV_DATA srv_data;

                            srv_data.adv_a_match_ext_adv = 0;
                            srv_data.adv_a_match_src = 0;
                            srv_data.source_id = p_data->p_brs_data->source_id;
                            bass_past_by_local_src(p_brs_char->handle, p_data->conn_handle,
                                                   srv_data);
                        }
                    }
                }
            }
        }
        break;

    case LE_AUDIO_MSG_BASS_CLIENT_BRS_DATA:
        {
            T_BASS_CLIENT_BRS_DATA *p_data = (T_BASS_CLIENT_BRS_DATA *)buf;
            APP_PRINT_INFO4("LE_AUDIO_MSG_BASS_CLIENT_BRS_DATA: conn_handle 0x%x, notify %d, read_cause 0x%x, char_instance_id %d",
                            p_data->conn_handle, p_data->notify, p_data->read_cause, p_data->char_instance_id);
            if (p_data->p_brs_data)
            {
                if (p_data->p_brs_data->brs_is_used)
                {
                    APP_PRINT_INFO7("LE_AUDIO_MSG_BASS_CLIENT_BRS_DATA: source_id %d, source_address_type 0x%x, source_address %s, source_adv_sid %d, pa_sync_state %d, bis_sync_state 0x%x, big_encryption %d",
                                    p_data->p_brs_data->source_id,
                                    p_data->p_brs_data->source_address_type,
                                    TRACE_BDADDR(p_data->p_brs_data->source_address),
                                    p_data->p_brs_data->source_adv_sid,
                                    p_data->p_brs_data->pa_sync_state,
                                    p_data->p_brs_data->bis_sync_state,
                                    p_data->p_brs_data->big_encryption);
                    if (p_data->p_brs_data->num_subgroups)
                    {
                        APP_PRINT_INFO4("LE_AUDIO_MSG_BASS_CLIENT_BRS_DATA: num_subgroups %d, bis_info_size %d, bis_sync 0x%x, metadata_len %d",
                                        p_data->p_brs_data->num_subgroups,
                                        p_data->p_brs_data->bis_info_size,
                                        p_data->p_brs_data->p_cp_bis_info[0].bis_sync,
                                        p_data->p_brs_data->p_cp_bis_info[0].metadata_len);
                    }
                    if (p_data->p_brs_data->big_encryption == BIG_BROADCAST_CODE_REQUIRED)
                    {
                        T_BASS_CP_SET_BROADCAST_CODE bc_data;
                        bc_data.source_id = p_data->p_brs_data->source_id;
                        memcpy(bc_data.broadcast_code, brs_broadcast_code, BROADCAST_CODE_LEN);
                        bass_cp_set_broadcast_code(p_data->conn_handle, &bc_data, false);
                    }
                }
                p_link = app_link_find_le_link_by_conn_handle(p_data->conn_handle);
                if (p_link)
                {
                    app_lea_link_update_brs_char(p_link, p_data);
                }
            }
        }
        break;
#endif
    default:
        break;
    }
    return cb_result;
}

void app_lea_ini_bap_init(void)
{
#if LE_AUDIO_BAP_SUPPORT
    T_BAP_ROLE_INFO role_info = {0};

    ble_audio_cback_register(app_lea_ini_bap_handle_msg);
#if BAP_UNICAST_CLIENT
    app_db.bap_role |= BAP_UNICAST_CLT_SRC_ROLE;
    app_db.bap_role |= BAP_UNICAST_CLT_SNK_ROLE;
    role_info.isoc_cig_max_num = APP_ISOC_CIG_MAX_NUM;
    role_info.isoc_cis_max_num = APP_ISOC_CIS_MAX_NUM;
#endif
#if BAP_BROADCAST_ASSISTANT
    app_db.bap_role |= BAP_BROADCAST_ASSISTANT_ROLE;
#endif
#if BAP_BROADCAST_SOURCE
    app_db.bap_role |= BAP_BROADCAST_SOURCE_ROLE;
    role_info.pa_adv_num = APP_MAX_PA_ADV_SET_NUM;
    role_info.isoc_big_broadcaster_num = APP_ISOC_BROADCASTER_MAX_BIG_HANDLE_NUM;
    role_info.isoc_bis_broadcaster_num = APP_ISOC_BROADCASTER_MAX_BIS_NUM;
#endif
    role_info.role_mask = app_db.bap_role;
    role_info.init_gap = true;
    bap_role_init(&role_info);
#endif
}
```

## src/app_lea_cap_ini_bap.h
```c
/*
 * Copyright (c) 2026, Realtek Semiconductor Corporation
 *
 * SPDX-License-Identifier: LicenseRef-Realtek-5-Clause
 */

#ifndef _APP_LEA_CAP_INI_BAP_H_
#define _APP_LEA_CAP_INI_BAP_H_

#ifdef  __cplusplus
extern "C" {
#endif      /* __cplusplus */

#include "ble_audio.h"
#include "ble_audio_group.h"

#define APP_ISOC_CIG_MAX_NUM                      2
#define APP_ISOC_CIS_MAX_NUM                      4
#define APP_MAX_PA_ADV_SET_NUM                    1
#define APP_ISOC_BROADCASTER_MAX_BIG_HANDLE_NUM   1
#define APP_ISOC_BROADCASTER_MAX_BIS_NUM          4

void app_lea_ini_bap_init(void);

#if (BAP_BROADCAST_ASSISTANT || BAP_BROADCAST_SOURCE)
void app_lea_ini_bst_reception_start(T_BLE_AUDIO_GROUP_HANDLE group_handle,
                                     T_BROADCAST_SOURCE_HANDLE source_handle);
void app_lea_ini_bst_reception_remove(T_BLE_AUDIO_GROUP_HANDLE group_handle,
                                      T_BROADCAST_SOURCE_HANDLE source_handle);
void app_lea_ini_bst_reception_stop(T_BLE_AUDIO_GROUP_HANDLE group_handle,
                                    T_BROADCAST_SOURCE_HANDLE source_handle);
void app_lea_link_brs_char_add_source_handle(void);
#endif

#ifdef  __cplusplus
}
#endif      /*  __cplusplus */

#endif
```

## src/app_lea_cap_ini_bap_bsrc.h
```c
/*
 * Copyright (c) 2026, Realtek Semiconductor Corporation
 *
 * SPDX-License-Identifier: LicenseRef-Realtek-5-Clause
 */

#ifndef _APP_LEA_CAP_INI_BAP_BSRC_H_
#define _APP_LEA_CAP_INI_BAP_BSRC_H_

#ifdef  __cplusplus
extern "C" {
#endif      /* __cplusplus */

#include "broadcast_source_sm.h"
#include "codec_qos.h"

#if BAP_BROADCAST_SOURCE
#define PRIMARY_ADV_INTERVAL_MIN          48
#define PRIMARY_ADV_INTERVAL_MAX          48
#define PERIODIC_ADV_INTERVAL_MIN         160
#define PERIODIC_ADV_INTERVAL_MAX         160

typedef struct
{
    T_BROADCAST_SOURCE_HANDLE source_handle;
    T_BROADCAST_SOURCE_STATE state;
    T_BROADCAST_SOURCE_STATE prefer_state;
    uint8_t                  encryption;
    uint8_t                  group1_bis_num;
    uint8_t                  group1_idx;
    uint8_t                  group1_subgroup1_idx;
    uint8_t                  group1_bis1_idx;
    uint8_t                  group1_bis2_idx;
    uint8_t                  group1_bis3_idx;

    uint16_t                  max_sdu;
    uint32_t                  sdu_interval;
    T_CODEC_CFG               codec_cfg;
    T_QOS_CFG_PREFERRED       prefer_qos;

    uint8_t                   source_adv_sid;
    uint8_t                   broadcast_id[BROADCAST_ID_LEN];
    uint8_t                   source_address[GAP_BD_ADDR_LEN];

//Configure parameters
    uint8_t                   cfg_bis_num;
    T_CODEC_CFG_ITEM          cfg_codec_index;
    T_QOS_CFG_TYPE            cfg_qos_type;
    T_GAP_LOCAL_ADDR_TYPE     cfg_local_addr_type;
    bool                      cfg_encryption;
} T_BROADCAST_SOURCE_CB;

extern uint8_t brs_broadcast_code[16];//Just for test, app can change the value

void app_lea_bsrc_init(T_CODEC_CFG_ITEM index, T_QOS_CFG_TYPE qos_type, uint8_t bis_num,
                       T_GAP_LOCAL_ADDR_TYPE local_addr_type, bool encryption);
T_BROADCAST_SOURCE_HANDLE app_lea_bsrc_get_handle(uint8_t *bd_addr, uint8_t bd_type,
                                                  uint8_t adv_sid, uint8_t broadcast_id[3]);
bool app_lea_bsrc_start(void);
bool app_lea_bsrc_stop(bool release);
#endif

#ifdef  __cplusplus
}
#endif      /*  __cplusplus */

#endif
```

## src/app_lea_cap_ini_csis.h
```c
/*
 * Copyright (c) 2026, Realtek Semiconductor Corporation
 *
 * SPDX-License-Identifier: LicenseRef-Realtek-5-Clause
 */

#ifndef _APP_LEA_CAP_INI_CSIS_H_
#define _APP_LEA_CAP_INI_CSIS_H_

#ifdef  __cplusplus
extern "C" {
#endif      /* __cplusplus */

#include "gap.h"
#include "ble_audio.h"
#include "cap.h"

void app_lea_ini_csis_init(T_CAP_INIT_PARAMS *p_param);

#ifdef  __cplusplus
}
#endif      /*  __cplusplus */

#endif
```
